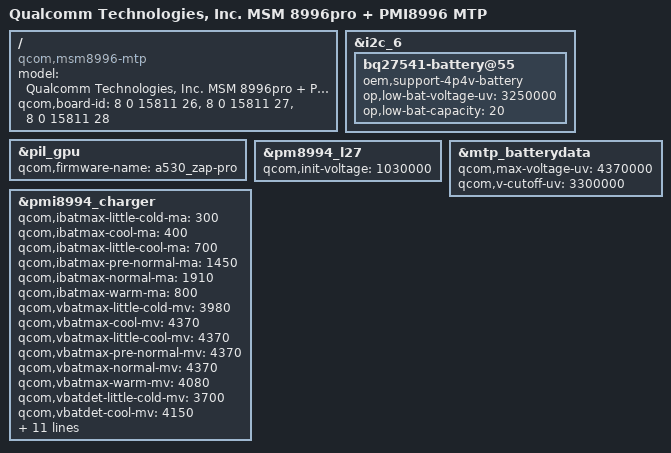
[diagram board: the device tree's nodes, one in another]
/* Copyright (c) 2016, The Linux Foundation. All rights reserved.
 *
 * This program is free software; you can redistribute it and/or modify
 * it under the terms of the GNU General Public License version 2 and
 * only version 2 as published by the Free Software Foundation.
 *
 * This program is distributed in the hope that it will be useful,
 * but WITHOUT ANY WARRANTY; without even the implied warranty of
 * MERCHANTABILITY or FITNESS FOR A PARTICULAR PURPOSE.  See the
 * GNU General Public License for more details.
 */


/dts-v1/;

#include "msm8996pro.dtsi"
#include "msm-pmi8996.dtsi"
#include "msm8996-camera-sensor-mtp-15811.dtsi"
#include "msm8996-mtp.dtsi"

/ {
	model = "Qualcomm Technologies, Inc. MSM 8996pro + PMI8996 MTP";
	compatible = "qcom,msm8996-mtp", "qcom,msm8996", "qcom,mtp";
	qcom,board-id = <8 0 15811 26>, <8 0 15811 27>, <8 0 15811 28>;
};

&i2c_6 {
	bq27541-battery@55 {
		oem,support-4p4v-battery;
		op,low-bat-voltage-uv = <3250000>;
		op,low-bat-capacity = <20>;
	};
};

&pil_gpu {
	qcom,firmware-name = "a530_zap-pro";
};

&pm8994_l27 {
	qcom,init-voltage = <1030000>;
};

&mtp_batterydata {
	qcom,max-voltage-uv = <4370000>;
	qcom,v-cutoff-uv = <3300000>;
};

&pmi8994_charger {
	/* ibatmax setting for different temp regions */
	qcom,ibatmax-little-cold-ma = <300>;
	qcom,ibatmax-cool-ma = <400>;
	qcom,ibatmax-little-cool-ma = <700>;
	qcom,ibatmax-pre-normal-ma = <1450>;
	qcom,ibatmax-normal-ma = <1910>;
	qcom,ibatmax-warm-ma = <800>;
	/* vbatmax setting for different temp regions */
	qcom,vbatmax-little-cold-mv = <3980>;
	qcom,vbatmax-cool-mv = <4370>;
	qcom,vbatmax-little-cool-mv = <4370>;
	qcom,vbatmax-pre-normal-mv = <4370>;
	qcom,vbatmax-normal-mv = <4370>;
	qcom,vbatmax-warm-mv = <4080>;
	/* vbatdet setting for different temp regions */
	qcom,vbatdet-little-cold-mv = <3700>;
	qcom,vbatdet-cool-mv = <4150>;
	qcom,vbatdet-little-cool-mv = <4270>;
	qcom,vbatdet-pre-normal-mv = <4270>;
	qcom,vbatdet-normal-mv = <4270>;
	qcom,vbatdet-warm-mv = <3980>;
	/* vbatdet setting for different temp regions */
	qcom,cold-bat-decidegc = <30>;
	qcom,little-cold-bat-decidegc = <0>;
	qcom,cool-bat-decidegc = <50>;
	qcom,little-cool-bat-decidegc = <120>;
	qcom,pre-normal-bat-decidegc = <160>;
	qcom,warm-bat-decidegc = <450>;
	qcom,hot-bat-decidegc = <530>;
};
